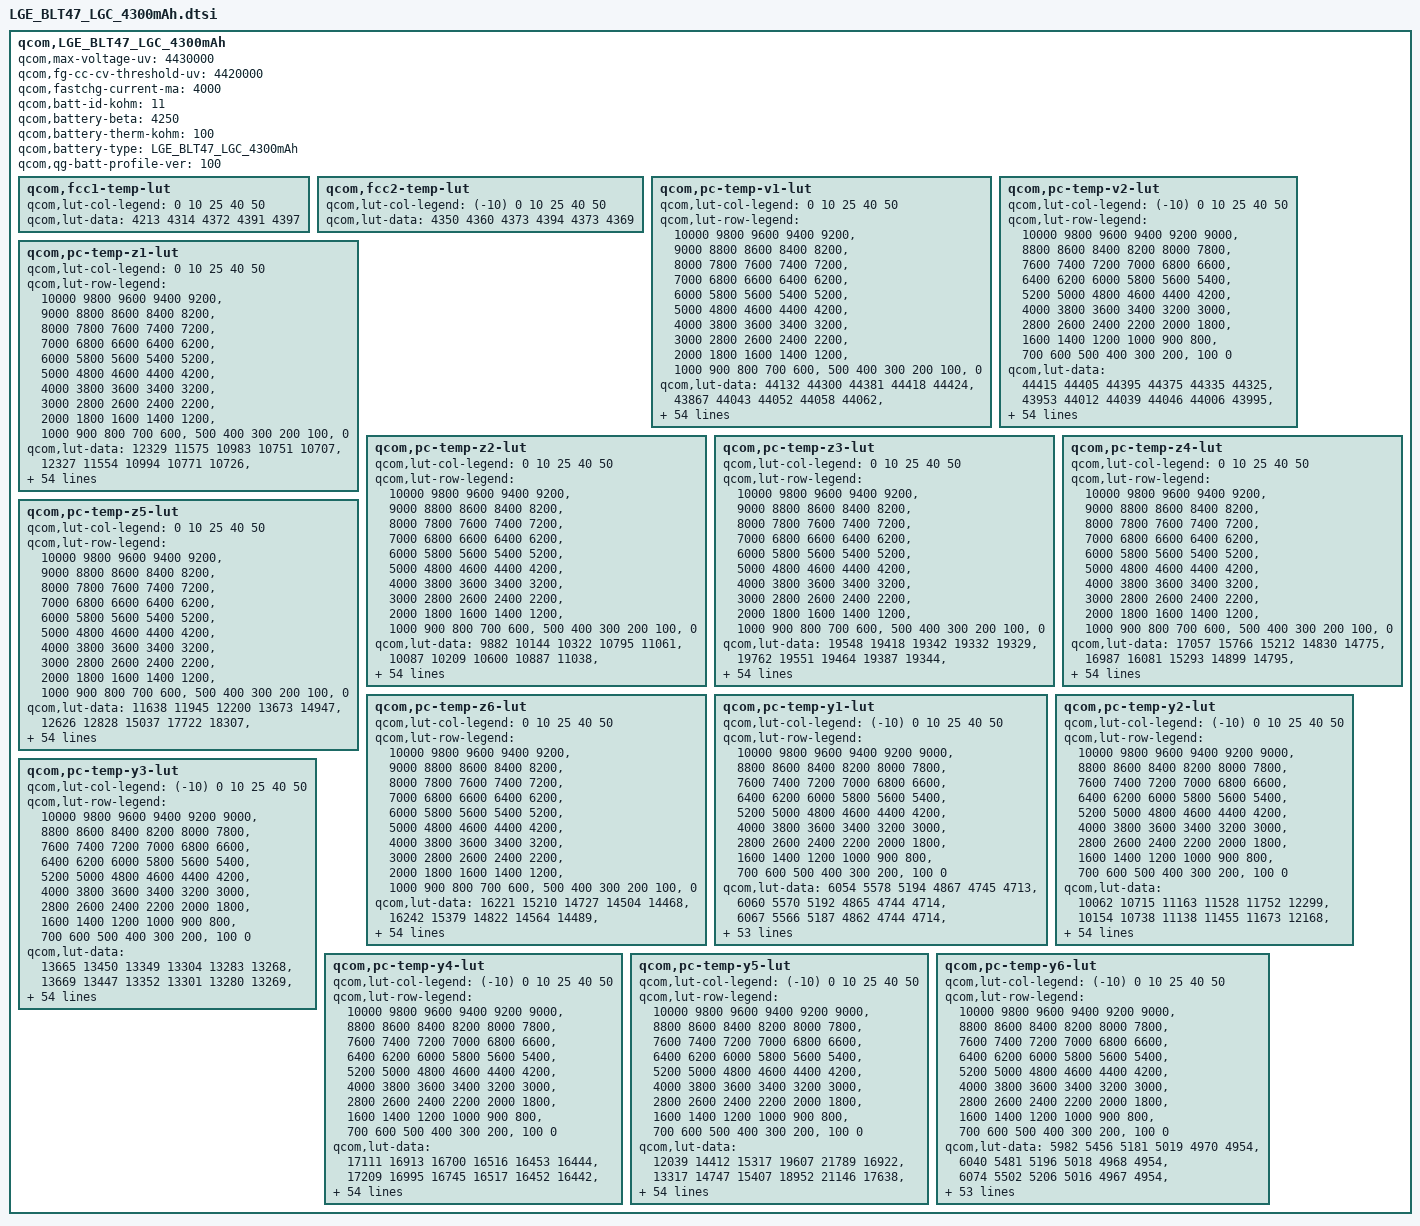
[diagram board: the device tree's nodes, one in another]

qcom,LGE_BLT47_LGC_4300mAh {
    /* 4435939_LGE_BLT47lgc_4300mAh_averaged_MasterSlave_Mar3rd2020 */
    qcom,max-voltage-uv = <4430000>;
    qcom,fg-cc-cv-threshold-uv = <4420000>;
    qcom,fastchg-current-ma = <4000>;
    qcom,batt-id-kohm = <11>;
    qcom,battery-beta = <4250>;
    qcom,battery-therm-kohm = <100>;
    qcom,battery-type = "LGE_BLT47_LGC_4300mAh";
    qcom,qg-batt-profile-ver = <100>;

	qcom,fcc1-temp-lut {
		qcom,lut-col-legend = <0 10 25 40 50>;
		qcom,lut-data = <4213 4314 4372 4391 4397>;
	};

	qcom,fcc2-temp-lut {
		qcom,lut-col-legend = <(-10) 0 10 25 40 50>;
		qcom,lut-data = <4350 4360 4373 4394 4373 4369>;
	};

	qcom,pc-temp-v1-lut {
		qcom,lut-col-legend = <0 10 25 40 50>;
		qcom,lut-row-legend = <10000 9800 9600 9400 9200>,
			<9000 8800 8600 8400 8200>,
			<8000 7800 7600 7400 7200>,
			<7000 6800 6600 6400 6200>,
			<6000 5800 5600 5400 5200>,
			<5000 4800 4600 4400 4200>,
			<4000 3800 3600 3400 3200>,
			<3000 2800 2600 2400 2200>,
			<2000 1800 1600 1400 1200>,
			<1000 900 800 700 600>,
			<500 400 300 200 100>,
			<0>;
		qcom,lut-data = <44132 44300 44381 44418 44424>,
			<43867 44043 44052 44058 44062>,
			<43617 43795 43805 43802 43804>,
			<43380 43552 43579 43578 43577>,
			<43145 43313 43343 43347 43347>,
			<42899 43074 43104 43112 43115>,
			<42650 42825 42861 42874 42881>,
			<42406 42572 42614 42630 42641>,
			<42164 42324 42364 42382 42396>,
			<41926 42080 42116 42137 42151>,
			<41694 41840 41870 41894 41906>,
			<41466 41605 41630 41655 41665>,
			<41246 41375 41397 41418 41430>,
			<41039 41153 41169 41184 41199>,
			<40836 40939 40949 40961 40974>,
			<40626 40730 40736 40745 40754>,
			<40414 40522 40530 40537 40542>,
			<40220 40317 40328 40335 40339>,
			<40047 40131 40138 40143 40146>,
			<39885 39962 39972 39969 39969>,
			<39725 39798 39813 39806 39802>,
			<39571 39639 39622 39621 39619>,
			<39419 39479 39389 39402 39408>,
			<39270 39279 39170 39188 39200>,
			<39121 38994 38986 38999 39008>,
			<38962 38762 38824 38826 38829>,
			<38787 38659 38696 38686 38684>,
			<38638 38589 38594 38571 38567>,
			<38526 38523 38503 38469 38462>,
			<38435 38462 38417 38373 38364>,
			<38374 38407 38341 38288 38275>,
			<38333 38352 38275 38214 38195>,
			<38300 38301 38218 38148 38122>,
			<38269 38256 38167 38090 38058>,
			<38244 38218 38123 38045 38008>,
			<38219 38182 38082 38002 37961>,
			<38201 38151 38044 37950 37899>,
			<38178 38120 38006 37891 37824>,
			<38137 38072 37956 37824 37747>,
			<38071 37991 37878 37750 37675>,
			<37986 37892 37781 37665 37594>,
			<37864 37779 37670 37554 37484>,
			<37719 37645 37537 37419 37347>,
			<37556 37477 37373 37259 37185>,
			<37391 37312 37211 37103 37032>,
			<37259 37188 37099 37002 36937>,
			<37218 37155 37074 36983 36917>,
			<37184 37123 37054 36967 36904>,
			<37156 37100 37034 36952 36892>,
			<37112 37068 37011 36922 36860>,
			<37002 36946 36851 36723 36636>,
			<36607 36543 36442 36304 36211>,
			<36039 35976 35876 35736 35640>,
			<35265 35197 35099 34956 34854>,
			<34041 33958 33885 33756 33651>,
			<30000 30000 30000 30000 30000>;
	};

	qcom,pc-temp-v2-lut {
		qcom,lut-col-legend = <(-10) 0 10 25 40 50>;
		qcom,lut-row-legend = <10000 9800 9600 9400 9200 9000>,
			<8800 8600 8400 8200 8000 7800>,
			<7600 7400 7200 7000 6800 6600>,
			<6400 6200 6000 5800 5600 5400>,
			<5200 5000 4800 4600 4400 4200>,
			<4000 3800 3600 3400 3200 3000>,
			<2800 2600 2400 2200 2000 1800>,
			<1600 1400 1200 1000 900 800>,
			<700 600 500 400 300 200>,
			<100 0>;
		qcom,lut-data = <44415 44405 44395 44375 44335 44325>,
			<43953 44012 44039 44046 44006 43995>,
			<43563 43666 43721 43749 43708 43697>,
			<43266 43379 43450 43490 43447 43437>,
			<43039 43140 43218 43266 43221 43213>,
			<42809 42901 42986 43039 42993 42986>,
			<42546 42643 42737 42796 42752 42746>,
			<42272 42380 42486 42551 42507 42502>,
			<41988 42125 42237 42305 42263 42259>,
			<41688 41875 41988 42058 42017 42015>,
			<41455 41624 41745 41815 41777 41774>,
			<41319 41356 41507 41575 41539 41537>,
			<41194 41103 41275 41340 41307 41304>,
			<40984 40907 41048 41111 41079 41075>,
			<40681 40745 40828 40888 40856 40852>,
			<40371 40564 40616 40671 40640 40638>,
			<40063 40342 40413 40458 40431 40431>,
			<39767 40104 40214 40253 40230 40232>,
			<39515 39866 40016 40064 40043 40044>,
			<39291 39623 39819 39882 39864 39863>,
			<39067 39391 39605 39681 39682 39680>,
			<38837 39170 39362 39459 39497 39498>,
			<38617 38960 39131 39238 39304 39308>,
			<38406 38766 38936 39020 39077 39084>,
			<38209 38581 38761 38815 38840 38848>,
			<38107 38396 38608 38657 38669 38676>,
			<38064 38187 38474 38531 38545 38551>,
			<38031 38033 38353 38420 38438 38444>,
			<37993 37968 38244 38319 38336 38342>,
			<37955 37926 38143 38225 38242 38247>,
			<37915 37889 38043 38139 38157 38160>,
			<37873 37858 37939 38057 38080 38080>,
			<37829 37826 37863 37984 38009 38006>,
			<37781 37790 37820 37918 37947 37944>,
			<37730 37751 37786 37857 37887 37883>,
			<37676 37709 37750 37796 37808 37796>,
			<37615 37663 37713 37736 37712 37678>,
			<37549 37612 37670 37668 37616 37564>,
			<37475 37551 37614 37587 37526 37467>,
			<37394 37480 37544 37500 37436 37374>,
			<37306 37398 37452 37412 37350 37286>,
			<37210 37296 37329 37312 37263 37200>,
			<37117 37181 37188 37186 37147 37085>,
			<37031 37051 37036 37029 36997 36937>,
			<36957 36910 36896 36890 36852 36799>,
			<36868 36788 36806 36852 36825 36775>,
			<36822 36747 36776 36838 36815 36764>,
			<36766 36717 36743 36814 36799 36749>,
			<36692 36679 36691 36780 36769 36718>,
			<36563 36627 36590 36679 36673 36608>,
			<36315 36476 36361 36338 36373 36293>,
			<35931 36069 35928 35807 35881 35790>,
			<35335 35404 35289 35132 35254 35164>,
			<34437 34462 34350 34220 34489 34421>,
			<32969 32973 32842 32988 33384 33302>,
			<29677 29536 29518 29514 29512 29512>;
	};

	qcom,pc-temp-z1-lut {
		qcom,lut-col-legend = <0 10 25 40 50>;
		qcom,lut-row-legend = <10000 9800 9600 9400 9200>,
			<9000 8800 8600 8400 8200>,
			<8000 7800 7600 7400 7200>,
			<7000 6800 6600 6400 6200>,
			<6000 5800 5600 5400 5200>,
			<5000 4800 4600 4400 4200>,
			<4000 3800 3600 3400 3200>,
			<3000 2800 2600 2400 2200>,
			<2000 1800 1600 1400 1200>,
			<1000 900 800 700 600>,
			<500 400 300 200 100>,
			<0>;
		qcom,lut-data = <12329 11575 10983 10751 10707>,
			<12327 11554 10994 10771 10726>,
			<12325 11563 10988 10770 10728>,
			<12322 11562 10981 10770 10730>,
			<12317 11552 10974 10770 10733>,
			<12304 11538 10965 10772 10736>,
			<12281 11526 10961 10773 10739>,
			<12260 11515 10960 10773 10740>,
			<12240 11508 10960 10772 10740>,
			<12219 11502 10959 10772 10741>,
			<12197 11498 10958 10772 10741>,
			<12176 11498 10957 10772 10741>,
			<12163 11500 10956 10772 10742>,
			<12155 11501 10955 10773 10744>,
			<12151 11498 10956 10775 10745>,
			<12148 11495 10958 10776 10747>,
			<12144 11498 10960 10778 10748>,
			<12146 11503 10961 10779 10750>,
			<12158 11506 10963 10781 10752>,
			<12173 11506 10966 10783 10753>,
			<12186 11507 10970 10785 10755>,
			<12202 11515 10974 10788 10757>,
			<12211 11530 10978 10790 10759>,
			<12221 11537 10982 10793 10762>,
			<12234 11539 10988 10796 10765>,
			<12238 11541 10993 10800 10768>,
			<12241 11548 10998 10803 10771>,
			<12245 11557 11001 10807 10774>,
			<12253 11562 11005 10810 10776>,
			<12264 11565 11010 10812 10778>,
			<12269 11569 11014 10814 10779>,
			<12270 11579 11018 10817 10782>,
			<12271 11593 11021 10820 10784>,
			<12276 11598 11024 10822 10787>,
			<12283 11598 11028 10825 10788>,
			<12292 11598 11032 10827 10789>,
			<12306 11605 11038 10830 10791>,
			<12323 11618 11045 10832 10793>,
			<12346 11630 11050 10834 10794>,
			<12376 11643 11054 10837 10796>,
			<12391 11653 11057 10839 10797>,
			<12385 11659 11061 10842 10799>,
			<12383 11666 11066 10844 10802>,
			<12389 11679 11073 10848 10804>,
			<12422 11694 11082 10852 10806>,
			<12397 11692 11089 10854 10809>,
			<12402 11695 11091 10857 10810>,
			<12433 11699 11094 10857 10811>,
			<12395 11696 11094 10858 10812>,
			<12400 11712 11097 10861 10813>,
			<12400 11720 11107 10865 10816>,
			<12414 11734 11119 10873 10824>,
			<12444 11758 11142 10886 10834>,
			<12475 11795 11165 10903 10850>,
			<12475 11795 11165 10903 10850>,
			<12475 11795 11165 10903 10850>;
	};

	qcom,pc-temp-z2-lut {
		qcom,lut-col-legend = <0 10 25 40 50>;
		qcom,lut-row-legend = <10000 9800 9600 9400 9200>,
			<9000 8800 8600 8400 8200>,
			<8000 7800 7600 7400 7200>,
			<7000 6800 6600 6400 6200>,
			<6000 5800 5600 5400 5200>,
			<5000 4800 4600 4400 4200>,
			<4000 3800 3600 3400 3200>,
			<3000 2800 2600 2400 2200>,
			<2000 1800 1600 1400 1200>,
			<1000 900 800 700 600>,
			<500 400 300 200 100>,
			<0>;
		qcom,lut-data = <9882 10144 10322 10795 11061>,
			<10087 10209 10600 10887 11038>,
			<10147 10276 10583 10885 11079>,
			<10159 10293 10551 10861 11149>,
			<10165 10246 10504 10849 11163>,
			<10170 10196 10437 10834 11138>,
			<10174 10175 10412 10826 11103>,
			<10173 10162 10434 10828 11049>,
			<10156 10159 10466 10831 10991>,
			<10135 10166 10489 10819 10985>,
			<10122 10173 10511 10769 11006>,
			<10111 10175 10532 10743 11034>,
			<10103 10176 10553 10751 11071>,
			<10098 10179 10573 10769 11111>,
			<10093 10195 10594 10807 11144>,
			<10085 10218 10614 10878 11173>,
			<10071 10242 10631 10912 11197>,
			<10061 10271 10644 10913 11215>,
			<10054 10298 10659 10913 11232>,
			<10049 10323 10684 10935 11259>,
			<10050 10350 10720 10977 11292>,
			<10061 10383 10770 11019 11313>,
			<10076 10421 10848 11065 11332>,
			<10097 10462 10891 11105 11342>,
			<10124 10515 10848 11137 11324>,
			<10155 10546 10786 11161 11280>,
			<10196 10532 10784 11142 11223>,
			<10224 10504 10821 11045 11102>,
			<10235 10497 10840 10984 11027>,
			<10241 10501 10785 10991 11043>,
			<10244 10507 10717 11005 11081>,
			<10245 10520 10718 11031 11125>,
			<10247 10541 10753 11091 11186>,
			<10253 10553 10793 11156 11260>,
			<10269 10561 10844 11217 11358>,
			<10284 10567 10891 11281 11465>,
			<10299 10574 10912 11355 11556>,
			<10316 10580 10925 11439 11641>,
			<10343 10592 10944 11489 11695>,
			<10377 10616 10985 11518 11726>,
			<10397 10631 11015 11535 11747>,
			<10402 10626 11012 11536 11768>,
			<10410 10619 11005 11528 11796>,
			<10434 10626 11025 11497 11835>,
			<10599 10714 11085 11510 11888>,
			<10648 10797 11115 11555 11921>,
			<10646 10799 11096 11560 11912>,
			<10499 10786 11050 11557 11912>,
			<10320 10833 11040 11559 12120>,
			<10273 10885 10983 11611 12234>,
			<10301 10936 11178 11431 11657>,
			<10177 10809 11107 11302 11464>,
			<9991 10733 11067 11233 11391>,
			<9778 10553 10938 11150 11366>,
			<9778 10553 10938 11150 11366>,
			<9778 10553 10938 11150 11366>;
	};

	qcom,pc-temp-z3-lut {
		qcom,lut-col-legend = <0 10 25 40 50>;
		qcom,lut-row-legend = <10000 9800 9600 9400 9200>,
			<9000 8800 8600 8400 8200>,
			<8000 7800 7600 7400 7200>,
			<7000 6800 6600 6400 6200>,
			<6000 5800 5600 5400 5200>,
			<5000 4800 4600 4400 4200>,
			<4000 3800 3600 3400 3200>,
			<3000 2800 2600 2400 2200>,
			<2000 1800 1600 1400 1200>,
			<1000 900 800 700 600>,
			<500 400 300 200 100>,
			<0>;
		qcom,lut-data = <19548 19418 19342 19332 19329>,
			<19762 19551 19464 19387 19344>,
			<19809 19639 19491 19396 19353>,
			<19808 19664 19503 19400 19358>,
			<19807 19668 19502 19400 19359>,
			<19796 19670 19497 19396 19356>,
			<19774 19670 19490 19391 19352>,
			<19755 19668 19475 19385 19345>,
			<19740 19664 19460 19377 19336>,
			<19725 19642 19453 19367 19332>,
			<19711 19617 19448 19355 19331>,
			<19696 19601 19442 19348 19328>,
			<19684 19588 19432 19347 19322>,
			<19674 19577 19422 19346 19315>,
			<19667 19569 19417 19341 19313>,
			<19667 19563 19413 19333 19312>,
			<19671 19555 19411 19329 19311>,
			<19675 19548 19409 19329 19310>,
			<19681 19542 19407 19329 19309>,
			<19688 19537 19402 19328 19308>,
			<19698 19534 19397 19326 19308>,
			<19712 19531 19400 19326 19307>,
			<19719 19529 19426 19336 19308>,
			<19717 19531 19443 19344 19310>,
			<19713 19553 19425 19345 19314>,
			<19715 19570 19398 19344 19323>,
			<19725 19563 19398 19347 19329>,
			<19733 19547 19419 19364 19335>,
			<19730 19540 19434 19375 19338>,
			<19724 19537 19439 19373 19336>,
			<19717 19536 19441 19367 19333>,
			<19707 19538 19439 19362 19331>,
			<19696 19543 19431 19356 19327>,
			<19689 19544 19424 19351 19324>,
			<19683 19542 19421 19346 19320>,
			<19675 19540 19419 19342 19317>,
			<19667 19537 19416 19342 19316>,
			<19657 19533 19413 19344 19316>,
			<19649 19528 19410 19344 19316>,
			<19641 19522 19405 19340 19314>,
			<19633 19516 19400 19335 19312>,
			<19622 19510 19395 19334 19313>,
			<19609 19504 19390 19334 19313>,
			<19592 19495 19386 19328 19309>,
			<19529 19465 19376 19321 19303>,
			<19495 19442 19365 19319 19301>,
			<19470 19430 19360 19313 19301>,
			<19415 19431 19358 19313 19300>,
			<19341 19405 19358 19310 19291>,
			<19332 19374 19346 19309 19289>,
			<19326 19368 19345 19323 19307>,
			<19336 19341 19343 19329 19309>,
			<19345 19323 19340 19330 19310>,
			<19347 19324 19347 19332 19314>,
			<19347 19324 19347 19332 19314>,
			<19347 19324 19347 19332 19314>;
	};

	qcom,pc-temp-z4-lut {
		qcom,lut-col-legend = <0 10 25 40 50>;
		qcom,lut-row-legend = <10000 9800 9600 9400 9200>,
			<9000 8800 8600 8400 8200>,
			<8000 7800 7600 7400 7200>,
			<7000 6800 6600 6400 6200>,
			<6000 5800 5600 5400 5200>,
			<5000 4800 4600 4400 4200>,
			<4000 3800 3600 3400 3200>,
			<3000 2800 2600 2400 2200>,
			<2000 1800 1600 1400 1200>,
			<1000 900 800 700 600>,
			<500 400 300 200 100>,
			<0>;
		qcom,lut-data = <17057 15766 15212 14830 14775>,
			<16987 16081 15293 14899 14795>,
			<16821 15784 15175 14879 14796>,
			<16463 15541 15004 14822 14768>,
			<16108 15358 14920 14782 14745>,
			<15890 15207 14863 14749 14724>,
			<15715 15098 14823 14730 14711>,
			<15574 15011 14794 14721 14708>,
			<15459 14948 14772 14716 14706>,
			<15365 14895 14758 14714 14702>,
			<15292 14861 14746 14713 14694>,
			<15233 14850 14740 14712 14688>,
			<15178 14843 14736 14703 14685>,
			<15122 14835 14733 14693 14683>,
			<15076 14821 14729 14689 14678>,
			<15046 14811 14723 14687 14670>,
			<15026 14810 14718 14684 14663>,
			<15003 14809 14714 14678 14658>,
			<14972 14807 14711 14672 14653>,
			<14939 14794 14709 14668 14648>,
			<14904 14783 14707 14665 14644>,
			<14866 14783 14710 14667 14646>,
			<14849 14784 14730 14694 14679>,
			<14849 14794 14757 14726 14712>,
			<14850 14872 14804 14747 14722>,
			<14855 14934 14852 14764 14729>,
			<14883 14931 14851 14762 14727>,
			<14910 14922 14813 14728 14707>,
			<14926 14910 14781 14699 14688>,
			<14938 14892 14762 14690 14677>,
			<14940 14874 14749 14684 14669>,
			<14932 14858 14746 14682 14664>,
			<14922 14843 14745 14680 14659>,
			<14912 14833 14745 14680 14658>,
			<14901 14827 14745 14680 14658>,
			<14889 14822 14746 14681 14658>,
			<14878 14817 14749 14686 14665>,
			<14865 14812 14753 14701 14688>,
			<14850 14811 14756 14707 14698>,
			<14832 14811 14758 14706 14691>,
			<14819 14811 14760 14705 14682>,
			<14812 14798 14753 14698 14672>,
			<14801 14775 14736 14687 14664>,
			<14776 14755 14722 14686 14666>,
			<14734 14720 14699 14681 14666>,
			<14725 14692 14678 14665 14655>,
			<14738 14690 14670 14659 14645>,
			<14795 14680 14659 14643 14632>,
			<14870 14696 14649 14634 14629>,
			<14872 14722 14654 14634 14631>,
			<14868 14723 14667 14632 14624>,
			<14871 14763 14670 14626 14620>,
			<14875 14783 14670 14623 14618>,
			<14885 14787 14661 14624 14620>,
			<14885 14787 14661 14624 14620>,
			<14885 14787 14661 14624 14620>;
	};

	qcom,pc-temp-z5-lut {
		qcom,lut-col-legend = <0 10 25 40 50>;
		qcom,lut-row-legend = <10000 9800 9600 9400 9200>,
			<9000 8800 8600 8400 8200>,
			<8000 7800 7600 7400 7200>,
			<7000 6800 6600 6400 6200>,
			<6000 5800 5600 5400 5200>,
			<5000 4800 4600 4400 4200>,
			<4000 3800 3600 3400 3200>,
			<3000 2800 2600 2400 2200>,
			<2000 1800 1600 1400 1200>,
			<1000 900 800 700 600>,
			<500 400 300 200 100>,
			<0>;
		qcom,lut-data = <11638 11945 12200 13673 14947>,
			<12626 12828 15037 17722 18307>,
			<13127 13892 16266 18698 18797>,
			<13363 14611 17250 19286 19693>,
			<13579 14999 17826 20016 20346>,
			<13884 15392 18222 20934 20916>,
			<14222 16098 18550 21381 21203>,
			<14545 17036 18823 21124 20450>,
			<14856 17796 19083 20565 19234>,
			<15154 18490 19451 19766 19072>,
			<15433 18894 19878 18481 19344>,
			<15697 18874 19965 17911 19490>,
			<15946 18802 19474 18370 18809>,
			<16187 18831 19040 18911 17932>,
			<16421 19377 19170 18713 17953>,
			<16641 19947 19543 17956 18455>,
			<16871 20124 19878 17675 18976>,
			<17155 20233 20216 18166 19406>,
			<17557 20500 20592 18837 19902>,
			<18182 21367 20941 19238 20779>,
			<19492 22572 21400 19582 21944>,
			<22388 23862 24290 20350 22207>,
			<25394 25568 36852 22793 20982>,
			<27707 28519 44766 24586 19386>,
			<30066 35339 35456 22166 18004>,
			<33518 40114 21704 17606 16743>,
			<38975 36693 19676 16952 16672>,
			<42184 29647 20496 19533 18200>,
			<41541 26862 21711 22246 20045>,
			<39938 25975 24231 23993 21516>,
			<38150 25602 27158 25494 23014>,
			<35691 26542 28686 26779 24710>,
			<33730 28648 29662 27937 26701>,
			<33017 30297 30713 28826 28172>,
			<32572 31718 32302 29600 29197>,
			<32217 32749 33480 30117 29864>,
			<31854 33353 33347 30053 28999>,
			<31629 33845 32584 29559 25743>,
			<32362 34161 31542 28711 23637>,
			<34415 34415 29510 25841 22729>,
			<35292 34535 27845 23292 22244>,
			<34961 34366 27571 23561 22745>,
			<34506 34070 27439 24285 23735>,
			<33628 33928 27224 22116 21327>,
			<31321 33683 27696 20974 19611>,
			<26626 33174 29585 23121 20659>,
			<21466 27552 28427 22425 22446>,
			<16949 28599 28923 25723 26373>,
			<12788 20798 30838 27617 24692>,
			<12609 17065 24323 26411 22311>,
			<12561 16796 22016 28263 27277>,
			<12730 14249 19708 32690 30229>,
			<12585 13242 18676 35546 33428>,
			<12397 13146 20436 39383 41003>,
			<12397 13146 20436 39383 41003>,
			<12397 13146 20436 39383 41003>;
	};

	qcom,pc-temp-z6-lut {
		qcom,lut-col-legend = <0 10 25 40 50>;
		qcom,lut-row-legend = <10000 9800 9600 9400 9200>,
			<9000 8800 8600 8400 8200>,
			<8000 7800 7600 7400 7200>,
			<7000 6800 6600 6400 6200>,
			<6000 5800 5600 5400 5200>,
			<5000 4800 4600 4400 4200>,
			<4000 3800 3600 3400 3200>,
			<3000 2800 2600 2400 2200>,
			<2000 1800 1600 1400 1200>,
			<1000 900 800 700 600>,
			<500 400 300 200 100>,
			<0>;
		qcom,lut-data = <16221 15210 14727 14504 14468>,
			<16242 15379 14822 14564 14489>,
			<16218 15293 14779 14559 14493>,
			<16037 15208 14714 14538 14485>,
			<15835 15122 14676 14521 14477>,
			<15711 15044 14648 14506 14468>,
			<15606 14988 14624 14495 14460>,
			<15519 14944 14603 14488 14454>,
			<15445 14904 14586 14482 14450>,
			<15382 14865 14575 14475 14445>,
			<15328 14836 14567 14469 14441>,
			<15282 14822 14560 14463 14437>,
			<15243 14812 14553 14459 14433>,
			<15204 14802 14547 14454 14428>,
			<15176 14792 14542 14450 14424>,
			<15164 14783 14537 14445 14421>,
			<15157 14778 14534 14441 14418>,
			<15151 14774 14531 14439 14415>,
			<15146 14769 14529 14436 14412>,
			<15141 14761 14526 14434 14410>,
			<15137 14756 14523 14432 14408>,
			<15134 14756 14526 14433 14409>,
			<15133 14757 14549 14451 14423>,
			<15134 14764 14571 14470 14439>,
			<15138 14811 14582 14481 14449>,
			<15146 14848 14590 14489 14457>,
			<15167 14844 14591 14489 14458>,
			<15185 14835 14586 14484 14453>,
			<15191 14826 14582 14478 14447>,
			<15195 14818 14578 14473 14442>,
			<15195 14812 14574 14468 14437>,
			<15188 14808 14570 14464 14433>,
			<15180 14806 14566 14460 14430>,
			<15175 14803 14564 14457 14427>,
			<15171 14801 14563 14455 14424>,
			<15166 14799 14562 14453 14423>,
			<15160 14798 14563 14456 14426>,
			<15155 14797 14564 14463 14436>,
			<15150 14797 14564 14466 14440>,
			<15145 14797 14564 14464 14436>,
			<15141 14796 14563 14461 14431>,
			<15138 14792 14558 14458 14428>,
			<15134 14782 14550 14454 14425>,
			<15122 14774 14543 14451 14424>,
			<15084 14750 14530 14445 14421>,
			<15070 14732 14516 14437 14416>,
			<15064 14726 14511 14432 14411>,
			<15063 14723 14505 14426 14406>,
			<15059 14720 14502 14420 14399>,
			<15061 14718 14499 14420 14399>,
			<15068 14721 14506 14427 14406>,
			<15085 14734 14510 14429 14407>,
			<15107 14744 14513 14431 14409>,
			<15137 14764 14519 14435 14414>,
			<15137 14764 14519 14435 14414>,
			<15137 14764 14519 14435 14414>;
	};

	qcom,pc-temp-y1-lut {
		qcom,lut-col-legend = <(-10) 0 10 25 40 50>;
		qcom,lut-row-legend = <10000 9800 9600 9400 9200 9000>,
			<8800 8600 8400 8200 8000 7800>,
			<7600 7400 7200 7000 6800 6600>,
			<6400 6200 6000 5800 5600 5400>,
			<5200 5000 4800 4600 4400 4200>,
			<4000 3800 3600 3400 3200 3000>,
			<2800 2600 2400 2200 2000 1800>,
			<1600 1400 1200 1000 900 800>,
			<700 600 500 400 300 200>,
			<100 0>;
		qcom,lut-data = <6054 5578 5194 4867 4745 4713>,
			<6060 5570 5192 4865 4744 4714>,
			<6067 5566 5187 4862 4744 4714>,
			<6073 5564 5182 4859 4743 4715>,
			<6079 5565 5178 4857 4742 4716>,
			<6083 5568 5177 4855 4742 4716>,
			<6094 5575 5177 4855 4742 4716>,
			<6108 5582 5177 4854 4741 4716>,
			<6105 5581 5177 4854 4741 4716>,
			<6089 5574 5176 4853 4740 4716>,
			<6081 5570 5176 4852 4740 4717>,
			<6082 5576 5178 4851 4740 4717>,
			<6084 5583 5181 4850 4740 4718>,
			<6086 5586 5180 4850 4740 4718>,
			<6088 5591 5177 4850 4741 4718>,
			<6090 5592 5177 4851 4741 4719>,
			<6091 5591 5179 4852 4741 4720>,
			<6092 5590 5182 4853 4742 4721>,
			<6102 5595 5186 4854 4743 4722>,
			<6125 5602 5190 4855 4744 4722>,
			<6134 5605 5191 4856 4745 4723>,
			<6116 5603 5190 4857 4746 4724>,
			<6099 5602 5190 4858 4746 4725>,
			<6111 5606 5193 4859 4748 4726>,
			<6144 5614 5198 4862 4749 4726>,
			<6156 5618 5201 4864 4751 4727>,
			<6154 5620 5201 4866 4752 4729>,
			<6152 5621 5202 4868 4753 4730>,
			<6137 5623 5206 4871 4754 4731>,
			<6109 5625 5211 4874 4755 4731>,
			<6102 5626 5212 4877 4757 4731>,
			<6109 5625 5213 4879 4758 4733>,
			<6116 5624 5214 4881 4760 4735>,
			<6117 5625 5217 4886 4762 4736>,
			<6118 5626 5221 4891 4764 4737>,
			<6117 5627 5227 4894 4766 4738>,
			<6111 5629 5236 4896 4767 4739>,
			<6106 5632 5242 4898 4768 4740>,
			<6106 5640 5246 4902 4770 4742>,
			<6107 5650 5248 4906 4772 4743>,
			<6112 5651 5250 4910 4774 4745>,
			<6134 5643 5251 4915 4776 4746>,
			<6138 5641 5253 4922 4778 4747>,
			<6130 5642 5256 4928 4781 4749>,
			<6123 5653 5262 4927 4782 4751>,
			<6144 5672 5272 4933 4784 4752>,
			<6150 5675 5274 4939 4784 4752>,
			<6177 5684 5280 4943 4785 4753>,
			<6204 5687 5286 4945 4787 4753>,
			<6217 5692 5288 4950 4789 4754>,
			<6289 5701 5290 4961 4793 4757>,
			<6310 5729 5309 4971 4800 4763>,
			<6377 5764 5347 4990 4809 4770>,
			<6450 5835 5397 5018 4822 4782>,
			<6450 5835 5397 5018 4822 4782>,
			<6450 5835 5397 5018 4822 4782>;
	};

	qcom,pc-temp-y2-lut {
		qcom,lut-col-legend = <(-10) 0 10 25 40 50>;
		qcom,lut-row-legend = <10000 9800 9600 9400 9200 9000>,
			<8800 8600 8400 8200 8000 7800>,
			<7600 7400 7200 7000 6800 6600>,
			<6400 6200 6000 5800 5600 5400>,
			<5200 5000 4800 4600 4400 4200>,
			<4000 3800 3600 3400 3200 3000>,
			<2800 2600 2400 2200 2000 1800>,
			<1600 1400 1200 1000 900 800>,
			<700 600 500 400 300 200>,
			<100 0>;
		qcom,lut-data = <10062 10715 11163 11528 11752 12299>,
			<10154 10738 11138 11455 11673 12168>,
			<10244 10777 11111 11381 11594 12018>,
			<10328 10821 11083 11312 11521 11871>,
			<10400 10856 11053 11254 11459 11750>,
			<10456 10870 11021 11213 11412 11676>,
			<10490 10870 10986 11187 11377 11637>,
			<10523 10868 10952 11165 11351 11611>,
			<10626 10853 10926 11142 11338 11593>,
			<10859 10806 10904 11118 11329 11580>,
			<10969 10784 10894 11104 11327 11566>,
			<10845 10858 10890 11094 11354 11542>,
			<10694 10962 10888 11087 11386 11523>,
			<10731 11007 10905 11090 11393 11525>,
			<10923 11033 10962 11099 11394 11540>,
			<11046 11071 11025 11116 11398 11564>,
			<11095 11161 11090 11159 11411 11636>,
			<11121 11235 11161 11221 11432 11704>,
			<10971 11236 11247 11301 11476 11709>,
			<10515 11229 11337 11399 11559 11696>,
			<10244 11227 11358 11468 11664 11722>,
			<9962 11234 11329 11522 11845 11965>,
			<9719 11241 11306 11556 11966 12181>,
			<9692 11179 11312 11568 11921 12195>,
			<9683 11037 11330 11578 11833 12183>,
			<9677 10987 11347 11596 11815 12180>,
			<9672 10982 11369 11628 11847 12196>,
			<9669 10976 11380 11662 11895 12226>,
			<9666 10942 11370 11698 11997 12286>,
			<9664 10857 11348 11734 12130 12370>,
			<9663 10670 11332 11762 12194 12443>,
			<9662 10114 11321 11787 12241 12529>,
			<9662 9725 11303 11796 12293 12633>,
			<9662 9693 11251 11790 12433 12854>,
			<9662 9677 11171 11779 12586 13090>,
			<9662 9670 11083 11759 12550 13080>,
			<9662 9666 10977 11715 12324 12876>,
			<9662 9664 10884 11667 12166 12718>,
			<9662 9663 10816 11596 12110 12656>,
			<9662 9663 10749 11515 12071 12609>,
			<9662 9662 10670 11438 12033 12557>,
			<9662 9661 10565 11353 11999 12506>,
			<9661 9661 10195 11251 11976 12475>,
			<9661 9660 9823 11167 11942 12460>,
			<9660 9660 9824 11198 11882 12379>,
			<9660 9660 9750 11136 11836 12239>,
			<9659 9659 9709 11070 11764 12135>,
			<9658 9659 9690 11027 11779 12058>,
			<9656 9658 9679 10999 11687 11891>,
			<9655 9658 9671 10957 11602 11834>,
			<9653 9657 9666 10915 11579 11840>,
			<9651 9654 9662 10835 11513 11736>,
			<9650 9652 9657 10793 11452 11615>,
			<9650 9651 9654 10785 11439 11668>,
			<9650 9651 9654 10785 11439 11668>,
			<9650 9651 9654 10785 11439 11668>;
	};

	qcom,pc-temp-y3-lut {
		qcom,lut-col-legend = <(-10) 0 10 25 40 50>;
		qcom,lut-row-legend = <10000 9800 9600 9400 9200 9000>,
			<8800 8600 8400 8200 8000 7800>,
			<7600 7400 7200 7000 6800 6600>,
			<6400 6200 6000 5800 5600 5400>,
			<5200 5000 4800 4600 4400 4200>,
			<4000 3800 3600 3400 3200 3000>,
			<2800 2600 2400 2200 2000 1800>,
			<1600 1400 1200 1000 900 800>,
			<700 600 500 400 300 200>,
			<100 0>;
		qcom,lut-data = <13665 13450 13349 13304 13283 13268>,
			<13669 13447 13352 13301 13280 13269>,
			<13668 13444 13354 13300 13279 13270>,
			<13664 13442 13356 13298 13278 13271>,
			<13657 13441 13358 13298 13277 13272>,
			<13648 13441 13360 13298 13277 13273>,
			<13636 13442 13361 13298 13278 13274>,
			<13621 13443 13362 13299 13279 13274>,
			<13605 13443 13363 13300 13279 13275>,
			<13585 13442 13364 13301 13280 13275>,
			<13562 13440 13365 13301 13280 13276>,
			<13528 13424 13365 13302 13284 13276>,
			<13500 13406 13365 13302 13286 13276>,
			<13498 13405 13363 13304 13287 13276>,
			<13499 13407 13358 13308 13287 13276>,
			<13499 13409 13354 13310 13287 13277>,
			<13478 13410 13351 13311 13286 13279>,
			<13453 13412 13349 13311 13285 13281>,
			<13442 13407 13350 13310 13286 13281>,
			<13434 13394 13352 13306 13287 13278>,
			<13433 13383 13351 13304 13288 13278>,
			<13454 13376 13342 13304 13288 13279>,
			<13475 13368 13333 13303 13288 13281>,
			<13465 13359 13329 13298 13285 13278>,
			<13436 13348 13326 13292 13278 13272>,
			<13429 13342 13323 13289 13276 13270>,
			<13474 13338 13322 13288 13275 13270>,
			<13542 13336 13320 13288 13275 13270>,
			<13617 13334 13317 13288 13275 13270>,
			<13706 13333 13314 13289 13274 13272>,
			<13783 13335 13313 13289 13274 13272>,
			<13850 13361 13313 13288 13274 13271>,
			<13905 13396 13313 13288 13275 13270>,
			<13946 13439 13315 13288 13275 13271>,
			<13979 13494 13319 13288 13275 13272>,
			<14006 13552 13324 13288 13275 13271>,
			<14028 13618 13332 13289 13273 13270>,
			<14048 13685 13339 13289 13273 13268>,
			<14069 13753 13347 13289 13273 13267>,
			<14089 13820 13353 13289 13273 13267>,
			<14110 13878 13354 13290 13273 13267>,
			<14131 13929 13356 13293 13274 13268>,
			<14160 13974 13359 13297 13275 13269>,
			<14203 14012 13369 13299 13275 13269>,
			<14253 14022 13374 13295 13274 13268>,
			<14267 14037 13391 13297 13275 13270>,
			<14367 14111 13421 13301 13278 13271>,
			<14493 14184 13456 13303 13279 13273>,
			<14794 14257 13502 13312 13281 13277>,
			<15210 14354 13573 13318 13283 13277>,
			<15912 14511 13671 13318 13283 13276>,
			<17222 14922 13831 13326 13285 13277>,
			<19863 15931 14199 13341 13287 13278>,
			<26548 18164 14939 13365 13291 13281>,
			<26548 18164 14939 13365 13291 13281>,
			<26548 18164 14939 13365 13291 13281>;
	};

	qcom,pc-temp-y4-lut {
		qcom,lut-col-legend = <(-10) 0 10 25 40 50>;
		qcom,lut-row-legend = <10000 9800 9600 9400 9200 9000>,
			<8800 8600 8400 8200 8000 7800>,
			<7600 7400 7200 7000 6800 6600>,
			<6400 6200 6000 5800 5600 5400>,
			<5200 5000 4800 4600 4400 4200>,
			<4000 3800 3600 3400 3200 3000>,
			<2800 2600 2400 2200 2000 1800>,
			<1600 1400 1200 1000 900 800>,
			<700 600 500 400 300 200>,
			<100 0>;
		qcom,lut-data = <17111 16913 16700 16516 16453 16444>,
			<17209 16995 16745 16517 16452 16442>,
			<17345 17090 16780 16516 16450 16438>,
			<17484 17179 16805 16516 16449 16435>,
			<17590 17244 16820 16515 16448 16432>,
			<17630 17267 16824 16513 16447 16430>,
			<17619 17253 16815 16511 16447 16430>,
			<17597 17230 16798 16508 16446 16430>,
			<17571 17215 16785 16508 16447 16430>,
			<17537 17201 16773 16508 16449 16431>,
			<17523 17196 16767 16509 16450 16433>,
			<17627 17204 16766 16513 16448 16435>,
			<17755 17219 16766 16518 16447 16438>,
			<17728 17239 16774 16521 16449 16442>,
			<17571 17266 16800 16523 16455 16448>,
			<17422 17273 16822 16528 16463 16452>,
			<17300 17221 16841 16541 16472 16454>,
			<17198 17144 16852 16560 16483 16456>,
			<17138 17088 16845 16590 16495 16464>,
			<17097 17037 16822 16625 16510 16480>,
			<17039 16984 16792 16629 16525 16495>,
			<16924 16931 16744 16606 16542 16510>,
			<16817 16877 16696 16576 16552 16519>,
			<16766 16828 16663 16538 16522 16497>,
			<16732 16780 16637 16501 16465 16452>,
			<16723 16715 16620 16495 16451 16440>,
			<16726 16606 16609 16495 16451 16440>,
			<16731 16536 16599 16495 16451 16440>,
			<16740 16546 16590 16497 16454 16442>,
			<16755 16576 16581 16502 16460 16445>,
			<16768 16610 16560 16507 16467 16450>,
			<16779 16656 16517 16513 16475 16458>,
			<16788 16698 16494 16516 16484 16467>,
			<16795 16726 16502 16517 16495 16476>,
			<16802 16749 16518 16517 16504 16484>,
			<16806 16771 16540 16514 16499 16481>,
			<16809 16794 16575 16504 16475 16460>,
			<16810 16807 16609 16496 16458 16445>,
			<16807 16810 16640 16487 16450 16441>,
			<16800 16811 16664 16482 16446 16438>,
			<16790 16809 16673 16489 16448 16439>,
			<16776 16806 16677 16503 16453 16442>,
			<16772 16801 16696 16511 16454 16442>,
			<16772 16792 16709 16511 16454 16442>,
			<16774 16759 16678 16484 16442 16434>,
			<16754 16726 16684 16499 16448 16439>,
			<16771 16737 16706 16513 16454 16445>,
			<16802 16752 16733 16528 16460 16448>,
			<16901 16775 16775 16547 16465 16446>,
			<17012 16802 16829 16566 16461 16441>,
			<17186 16825 16864 16554 16460 16445>,
			<17554 16892 16881 16578 16479 16464>,
			<18486 17197 16979 16643 16528 16514>,
			<22638 18867 17674 16791 16670 16672>,
			<22638 18867 17674 16791 16670 16672>,
			<22638 18867 17674 16791 16670 16672>;
	};

	qcom,pc-temp-y5-lut {
		qcom,lut-col-legend = <(-10) 0 10 25 40 50>;
		qcom,lut-row-legend = <10000 9800 9600 9400 9200 9000>,
			<8800 8600 8400 8200 8000 7800>,
			<7600 7400 7200 7000 6800 6600>,
			<6400 6200 6000 5800 5600 5400>,
			<5200 5000 4800 4600 4400 4200>,
			<4000 3800 3600 3400 3200 3000>,
			<2800 2600 2400 2200 2000 1800>,
			<1600 1400 1200 1000 900 800>,
			<700 600 500 400 300 200>,
			<100 0>;
		qcom,lut-data = <12039 14412 15317 19607 21789 16922>,
			<13317 14747 15407 18952 21146 17638>,
			<14931 15067 15496 18031 19943 18669>,
			<16569 15365 15579 17064 18593 19759>,
			<17916 15633 15655 16273 17512 20649>,
			<18658 15865 15718 15880 17111 21082>,
			<18992 16089 15783 15736 17158 21225>,
			<19184 16264 15830 15642 17220 21300>,
			<19094 16331 15829 15558 17135 21205>,
			<18654 16370 15802 15402 16826 20745>,
			<18429 16365 15763 15207 16731 20189>,
			<18682 15594 15689 14880 18187 19533>,
			<19231 14690 15562 14626 19802 18774>,
			<20481 15024 15202 14778 19577 17875>,
			<22976 16583 14524 15184 18391 16858>,
			<24012 18162 14312 15290 17241 16563>,
			<23089 19871 14955 15003 16057 17309>,
			<22068 21106 16039 14762 15212 18044>,
			<22065 21243 17741 14810 15012 17299>,
			<22368 21276 19970 14984 14905 15412>,
			<22831 21378 20602 15745 15177 14989>,
			<24624 21930 20484 19213 18052 17109>,
			<26260 22592 20392 21527 20441 18968>,
			<23137 23065 20586 20621 20443 19052>,
			<15047 23466 21050 19157 20284 19029>,
			<12252 23336 21495 18746 20122 19014>,
			<12566 21000 21927 18612 19781 18983>,
			<12942 18197 22463 18576 19363 19007>,
			<13149 16076 23496 19109 18687 19293>,
			<13308 14241 24599 19873 17943 19687>,
			<13422 13675 24760 20155 17802 19548>,
			<13539 13508 24562 20282 17856 18342>,
			<13633 13445 24233 20616 17968 17576>,
			<13740 13559 23033 22917 18435 17992>,
			<13901 13767 21249 25156 19256 18839>,
			<14026 13857 19948 25167 20291 19766>,
			<14140 13903 18816 24738 21722 20969>,
			<14245 13952 18089 24043 22322 21499>,
			<14350 14193 17746 22213 22005 20927>,
			<14438 14509 17433 20248 21388 19936>,
			<14414 14544 16865 18892 20301 18962>,
			<14171 14426 15981 17958 18850 18019>,
			<13901 14281 14571 17735 18674 17924>,
			<13675 14123 13752 17879 18936 18067>,
			<13837 14143 14042 19578 20367 20992>,
			<13938 14343 13941 18107 19430 19132>,
			<14086 14284 14073 17857 19222 17904>,
			<14072 14366 14050 16565 17995 17754>,
			<13624 14119 13944 17108 17692 20915>,
			<13524 14154 14086 17809 20099 23154>,
			<12792 14082 14614 19410 23797 26524>,
			<11830 12913 14546 20578 26155 27245>,
			<10386 11396 13401 22351 26304 26579>,
			<9332 10022 11225 23242 25835 26016>,
			<9332 10022 11225 23242 25835 26016>,
			<9332 10022 11225 23242 25835 26016>;
	};

	qcom,pc-temp-y6-lut {
		qcom,lut-col-legend = <(-10) 0 10 25 40 50>;
		qcom,lut-row-legend = <10000 9800 9600 9400 9200 9000>,
			<8800 8600 8400 8200 8000 7800>,
			<7600 7400 7200 7000 6800 6600>,
			<6400 6200 6000 5800 5600 5400>,
			<5200 5000 4800 4600 4400 4200>,
			<4000 3800 3600 3400 3200 3000>,
			<2800 2600 2400 2200 2000 1800>,
			<1600 1400 1200 1000 900 800>,
			<700 600 500 400 300 200>,
			<100 0>;
		qcom,lut-data = <5982 5456 5181 5019 4970 4954>,
			<6040 5481 5196 5018 4968 4954>,
			<6074 5502 5206 5016 4967 4954>,
			<6092 5517 5212 5015 4966 4954>,
			<6099 5527 5214 5014 4965 4954>,
			<6100 5530 5215 5014 4965 4954>,
			<6087 5525 5211 5013 4965 4954>,
			<6064 5516 5205 5013 4966 4955>,
			<6040 5509 5201 5013 4967 4956>,
			<6012 5503 5197 5014 4967 4956>,
			<6000 5496 5194 5014 4968 4957>,
			<6009 5486 5192 5015 4970 4958>,
			<6021 5478 5191 5017 4972 4960>,
			<6013 5480 5192 5019 4973 4961>,
			<5977 5491 5195 5022 4975 4962>,
			<5937 5495 5197 5025 4977 4964>,
			<5896 5484 5200 5030 4979 4966>,
			<5858 5465 5202 5035 4982 4968>,
			<5836 5446 5201 5042 4986 4971>,
			<5820 5426 5195 5049 4991 4974>,
			<5804 5406 5187 5050 4995 4977>,
			<5785 5389 5167 5043 5000 4983>,
			<5768 5373 5147 5033 5003 4986>,
			<5756 5358 5136 5019 4992 4978>,
			<5747 5343 5127 5004 4971 4960>,
			<5747 5326 5121 5001 4965 4955>,
			<5798 5303 5118 5001 4965 4955>,
			<5871 5288 5115 5000 4965 4955>,
			<5943 5299 5112 5002 4965 4956>,
			<6023 5330 5109 5004 4967 4958>,
			<6089 5369 5104 5006 4969 4960>,
			<6144 5433 5095 5007 4971 4962>,
			<6188 5506 5090 5008 4974 4964>,
			<6220 5585 5096 5009 4978 4967>,
			<6246 5668 5109 5010 4981 4970>,
			<6267 5744 5126 5009 4979 4968>,
			<6284 5814 5154 5008 4972 4961>,
			<6299 5879 5185 5006 4966 4956>,
			<6313 5940 5219 5005 4964 4955>,
			<6327 5995 5255 5004 4963 4954>,
			<6342 6043 5285 5008 4964 4954>,
			<6357 6083 5313 5017 4967 4956>,
			<6380 6119 5346 5025 4968 4957>,
			<6416 6148 5383 5027 4968 4957>,
			<6462 6153 5381 5016 4964 4954>,
			<6478 6160 5413 5024 4967 4957>,
			<6563 6221 5463 5033 4971 4960>,
			<6681 6284 5519 5040 4974 4963>,
			<6977 6351 5592 5055 4977 4965>,
			<7367 6439 5688 5067 4978 4963>,
			<7987 6579 5798 5067 4978 4964>,
			<9124 6954 5955 5086 4985 4971>,
			<11371 7843 6311 5126 5002 4987>,
			<17176 9951 7115 5199 5047 5035>,
			<17176 9951 7115 5199 5047 5035>,
			<17176 9951 7115 5199 5047 5035>;
	};

};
